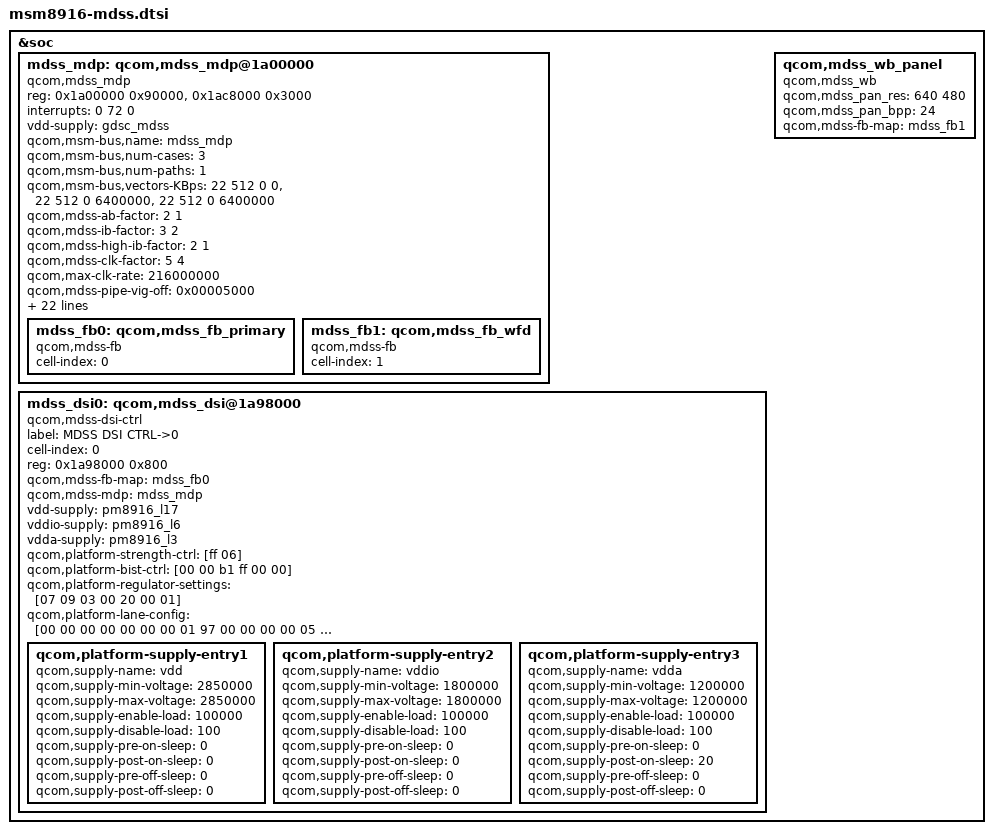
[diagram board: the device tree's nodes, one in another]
/* Copyright (c) 2013, The Linux Foundation. All rights reserved.
 *
 * This program is free software; you can redistribute it and/or modify
 * it under the terms of the GNU General Public License version 2 and
 * only version 2 as published by the Free Software Foundation.
 *
 * This program is distributed in the hope that it will be useful,
 * but WITHOUT ANY WARRANTY; without even the implied warranty of
 * MERCHANTABILITY or FITNESS FOR A PARTICULAR PURPOSE.  See the
 * GNU General Public License for more details.
 */

&soc {
	mdss_mdp: qcom,mdss_mdp@1a00000 {
		compatible = "qcom,mdss_mdp";
		reg = <0x1a00000 0x90000>,
			<0x1ac8000 0x3000>;
		reg-names = "mdp_phys", "vbif_phys";
		interrupts = <0 72 0>;
		vdd-supply = <&gdsc_mdss>;

		/* Bus Scale Settings */
		qcom,msm-bus,name = "mdss_mdp";
		qcom,msm-bus,num-cases = <3>;
		qcom,msm-bus,num-paths = <1>;
		qcom,msm-bus,vectors-KBps =
			<22 512 0 0>,
			<22 512 0 6400000>,
			<22 512 0 6400000>;

		/* Fudge factors */
		qcom,mdss-ab-factor = <2 1>;		/* 2 times    */
		qcom,mdss-ib-factor = <3 2>;		/* 1.5 times  */
		qcom,mdss-high-ib-factor = <2 1>;	/* 2 times    */
		qcom,mdss-clk-factor = <5 4>;		/* 1.25 times */

		qcom,max-clk-rate = <216000000>;
		qcom,mdss-pipe-vig-off = <0x00005000>;
		qcom,mdss-pipe-rgb-off = <0x00015000 0x00017000>;
		qcom,mdss-pipe-dma-off = <0x00025000>;
		qcom,mdss-pipe-vig-fetch-id = <1>;
		qcom,mdss-pipe-rgb-fetch-id = <7 8>;
		qcom,mdss-pipe-dma-fetch-id = <4>;
		qcom,mdss-smp-data = <8 8192>;

		qcom,mdss-ctl-off = <0x00002000 0x00002200 0x00002400>;
		qcom,mdss-mixer-intf-off = <0x00045000>;
		qcom,mdss-mixer-wb-off = <0x00048000>;
		qcom,mdss-dspp-off = <0x00055000>;
		qcom,mdss-pingpong-off = <0x00071000>;
		qcom,mdss-wb-off = <0x00065000 0x00065800 0x00066000>;
		qcom,mdss-intf-off = <0x00000000 0x0006b800>;
		qcom,mdss-rot-block-size = <64>;
		vdd-cx-supply = <&pm8916_s1_corner>;

		qcom,mdss-has-wfd-blk;
		qcom,vbif-settings = <0x004 0x00000001>,
				     <0x0d8 0x00000707>,
				     <0x124 0x00000003>;
		qcom,mdp-settings = <0x11e0 0x000000a5>,
				    <0x11e4 0x00000055>;

		mdss_fb0: qcom,mdss_fb_primary {
			cell-index = <0>;
			compatible = "qcom,mdss-fb";
		};

		mdss_fb1: qcom,mdss_fb_wfd {
			cell-index = <1>;
			compatible = "qcom,mdss-fb";
		};
	};

	mdss_dsi0: qcom,mdss_dsi@1a98000 {
		compatible = "qcom,mdss-dsi-ctrl";
		label = "MDSS DSI CTRL->0";
		cell-index = <0>;
		reg = <0x1a98000 0x800>;
		qcom,mdss-fb-map = <&mdss_fb0>;
		qcom,mdss-mdp = <&mdss_mdp>;
		vdd-supply = <&pm8916_l17>;
		vddio-supply = <&pm8916_l6>;
		vdda-supply = <&pm8916_l3>;
		qcom,platform-strength-ctrl = [ff 06];
		qcom,platform-bist-ctrl = [00 00 b1 ff 00 00];
		qcom,platform-regulator-settings = [07 09 03 00 20 00 01];
		qcom,platform-lane-config = [00 00 00 00 00 00 00 01 97
			00 00 00 00 05 00 00 01 97
			00 00 00 00 0a 00 00 01 97
			00 00 00 00 0f 00 00 01 97
			00 c0 00 00 00 00 00 01 bb];
		qcom,platform-supply-entry1 {
			qcom,supply-name = "vdd";
			qcom,supply-min-voltage = <2850000>;
			qcom,supply-max-voltage = <2850000>;
			qcom,supply-enable-load = <100000>;
			qcom,supply-disable-load = <100>;
			qcom,supply-pre-on-sleep = <0>;
			qcom,supply-post-on-sleep = <0>;
			qcom,supply-pre-off-sleep = <0>;
			qcom,supply-post-off-sleep = <0>;
		};
		qcom,platform-supply-entry2 {
			qcom,supply-name = "vddio";
			qcom,supply-min-voltage = <1800000>;
			qcom,supply-max-voltage = <1800000>;
			qcom,supply-enable-load = <100000>;
			qcom,supply-disable-load = <100>;
			qcom,supply-pre-on-sleep = <0>;
			qcom,supply-post-on-sleep = <0>;
			qcom,supply-pre-off-sleep = <0>;
			qcom,supply-post-off-sleep = <0>;
		};
		qcom,platform-supply-entry3 {
			qcom,supply-name = "vdda";
			qcom,supply-min-voltage = <1200000>;
			qcom,supply-max-voltage = <1200000>;
			qcom,supply-enable-load = <100000>;
			qcom,supply-disable-load = <100>;
			qcom,supply-pre-on-sleep = <0>;
			qcom,supply-post-on-sleep = <20>;
			qcom,supply-pre-off-sleep = <0>;
			qcom,supply-post-off-sleep = <0>;
		};
	};

	qcom,mdss_wb_panel {
		compatible = "qcom,mdss_wb";
		qcom,mdss_pan_res = <640 480>;
		qcom,mdss_pan_bpp = <24>;
		qcom,mdss-fb-map = <&mdss_fb1>;
	};
};

#include "dsi-panel-sim-video.dtsi"

